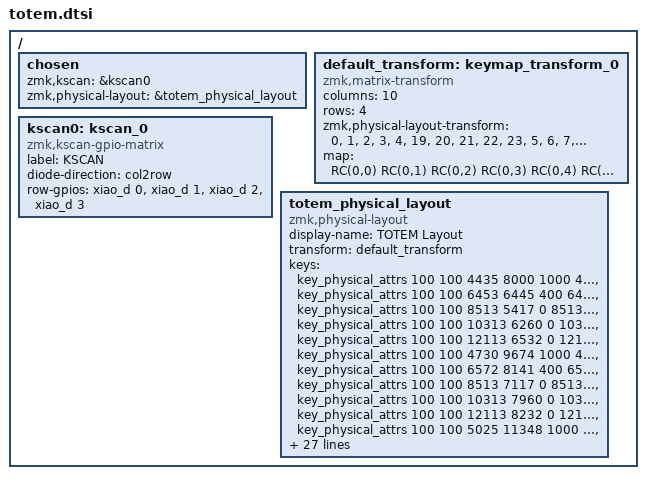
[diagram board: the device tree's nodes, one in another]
/*
 * Copyright (c) 2022 The ZMK Contributors
 *
 * SPDX-License-Identifier: MIT
 */

#include <dt-bindings/zmk/matrix_transform.h>
#include <physical_layouts.dtsi>

/ {
    chosen {
        zmk,kscan = &kscan0;
        //zmk,matrix_transform = &default_transform;
        zmk,physical-layout = &totem_physical_layout;
    };

    default_transform: keymap_transform_0 {
        compatible = "zmk,matrix-transform";
        columns = <10>;
        rows = <4>;
        
    zmk,physical-layout-transform = <
            // R0: Left(0-4) | Right(5-9)
            0, 1, 2, 3, 4, 19, 20, 21, 22, 23,  // <-- MUST have a comma here
            
            // R1: Left(0-4) | Right(5-9)
            5, 6, 7, 8, 9, 24, 25, 26, 27, 28,  // <-- MUST have a comma here
            
            // R2: Left(0-4) | Right(5-9)
            10, 11, 12, 13, 14, 29, 30, 31, 32, 33, // <-- MUST have a comma here
            
            // R3: Left(0-4) | Right(5-9)
            -1, 15, 16, 17, 18, 34, 35, 36, 37, -1  // <-- Final row needs no comma after last element
        >;
        
        // ... your 'map' property must also match this 4x10 structure

//             | SW01  | SW02  | SW03  | SW04  | SW05  |  | SW05  | SW04  | SW03  | SW02  | SW01  |
//             | SW06  | SW07  | SW08  | SW09  | SW10  |  | SW10  | SW09  | SW08  | SW07  | SW06  | 
//      | SW16 | SW11  | SW12  | SW13  | SW14  | SW15  |  | SW15  | SW14  | SW13  | SW12  | SW11  | SW16  |
//                             | SW17  | SW18  | SW19  |  | SW19  | SW18  | SW17  | 
        map = <
                RC(0,0) RC(0,1) RC(0,2) RC(0,3) RC(0,4)    RC(0,5) RC(0,6) RC(0,7) RC(0,8) RC(0,9)
                RC(1,0) RC(1,1) RC(1,2) RC(1,3) RC(1,4)    RC(1,5) RC(1,6) RC(1,7) RC(1,8) RC(1,9)
        RC(3,0) RC(2,0) RC(2,1) RC(2,2) RC(2,3) RC(2,4)    RC(2,5) RC(2,6) RC(2,7) RC(2,8) RC(2,9) RC(3,9)
                                RC(3,2) RC(3,3) RC(3,4)    RC(3,5) RC(3,6) RC(3,7)         
        >;
    };


    kscan0: kscan_0 {
        compatible = "zmk,kscan-gpio-matrix";
        label = "KSCAN";
        
        diode-direction = "col2row"; 
        row-gpios
            = <&xiao_d 0 (GPIO_ACTIVE_HIGH | GPIO_PULL_DOWN)>
            , <&xiao_d 1 (GPIO_ACTIVE_HIGH | GPIO_PULL_DOWN)>
            , <&xiao_d 2 (GPIO_ACTIVE_HIGH | GPIO_PULL_DOWN)>
            , <&xiao_d 3 (GPIO_ACTIVE_HIGH | GPIO_PULL_DOWN)>
            ;
    };
    
    totem_physical_layout: totem_physical_layout {
        compatible = "zmk,physical-layout";
        display-name = "TOTEM Layout";
        transform = <&default_transform>;
        
        keys  //                     w   h    x       y     rot    rx      ry
            = <&key_physical_attrs 100 100   4435    8000   1000   4435    8000>  // SWL1
            , <&key_physical_attrs 100 100   6453    6445    400   6453    6445>  // SWL2
            , <&key_physical_attrs 100 100   8513    5417      0   8513    5417>  // SWL3
            , <&key_physical_attrs 100 100  10313    6260      0  10313    6260>  // SWL4
            , <&key_physical_attrs 100 100  12113    6532      0  12113    6532>  // SWL5
            , <&key_physical_attrs 100 100   4730    9674   1000   4730    9674>  // SWL6
            , <&key_physical_attrs 100 100   6572    8141    400   6572    8141>  // SWL7
            , <&key_physical_attrs 100 100   8513    7117      0   8513    7117>  // SWL8
            , <&key_physical_attrs 100 100  10313    7960      0  10313    7960>  // SWL9
            , <&key_physical_attrs 100 100  12113    8232      0  12113    8232>  // SWL10
            , <&key_physical_attrs 100 100   5025   11348   1000   5025   11348>  // SWL11
            , <&key_physical_attrs 100 100   6690    9836    400   6690    9836>  // SWL12
            , <&key_physical_attrs 100 100   8513    8817      0   8513    8817>  // SWL13
            , <&key_physical_attrs 100 100  10313    9660      0  10313    9660>  // SWL14
            , <&key_physical_attrs 100 100  12113    9932      0  12113    9932>  // SWL15
            , <&key_physical_attrs 100 100   3115   10909   1000   3115   10909>  // SWL16
            , <&key_physical_attrs 100 100   9810   11731      0   9810   11731>  // SWL17
            , <&key_physical_attrs 100 100  11803   12009 (-1500) 11803   12009>  // SWL18
            , <&key_physical_attrs 100 100  13648   12776 (-3000) 13648   12776>  // SWL19
            
            , <&key_physical_attrs 100 100  25555    8001 (-1000) 25555    8001>  // SWR1
            , <&key_physical_attrs 100 100  23529    6445  (-400) 23529    6445>  // SWR2
            , <&key_physical_attrs 100 100  21475    5417      0  21475    5417>  // SWR3
            , <&key_physical_attrs 100 100  19675    6260      0  19675    6260>  // SWR4
            , <&key_physical_attrs 100 100  17875    6532      0  17875    6532>  // SWR5
            , <&key_physical_attrs 100 100  25260    9676 (-1000) 25260    9676>  // SWR6
            , <&key_physical_attrs 100 100  23410    8141  (-400) 23410    8141>  // SWR7
            , <&key_physical_attrs 100 100  21475    7117      0  21475    7117>  // SWR8
            , <&key_physical_attrs 100 100  19675    7960      0  19675    7960>  // SWR9
            , <&key_physical_attrs 100 100  17875    8241      0  17875    8241>  // SWR10
            , <&key_physical_attrs 100 100  24965   11350 (-1000) 24965   11350>  // SWR11
            , <&key_physical_attrs 100 100  23292    9837  (-400) 23292    9837>  // SWR12
            , <&key_physical_attrs 100 100  21475    8817      0  21475    8817>  // SWR13
            , <&key_physical_attrs 100 100  19675    9660      0  19675    9660>  // SWR14
            , <&key_physical_attrs 100 100  17875    9941      0  17875    9941>  // SWR15
            , <&key_physical_attrs 100 100  26870   10909 (-1000) 26870   10909>  // SWR16
            , <&key_physical_attrs 100 100  20178   11731      0  20178   11731>  // SWR17
            , <&key_physical_attrs 100 100  18188   12009   1500  18188   12009>  // SWR18
            , <&key_physical_attrs 100 100  16343   12776   3000  16343   12776>  // SWR19
            ;
    };
};
